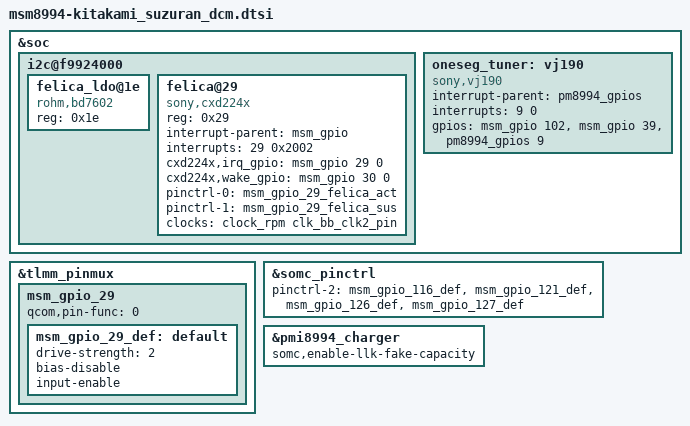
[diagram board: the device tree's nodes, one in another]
/* arch/arm/boot/dts/qcom/msm8994-kitakami_suzuran_dcm.dtsi
 *
 * This program is free software; you can redistribute it and/or modify
 * it under the terms of the GNU General Public License version 2 and
 * only version 2 as published by the Free Software Foundation.
 *
 * This program is distributed in the hope that it will be useful,
 * but WITHOUT ANY WARRANTY; without even the implied warranty of
 * MERCHANTABILITY or FITNESS FOR A PARTICULAR PURPOSE.  See the
 * GNU General Public License for more details.
 */
/*
 * Copyright (C) 2015 Sony Mobile Communications Inc.
 *
 * This program is free software; you can redistribute it and/or modify
 * it under the terms of the GNU General Public License version 2, as
 * published by the Free Software Foundation.
 */

&soc {
	i2c@f9924000 {
		felica_ldo@1e {
			compatible = "rohm,bd7602";
			reg = <0x1e>;
		};
		felica@29 {
			compatible = "sony,cxd224x";
			reg = <0x29>;
			interrupt-parent = <&msm_gpio>;
			interrupts = <29 0x2002>;
			cxd224x,irq_gpio = <&msm_gpio 29 0>;
			cxd224x,wake_gpio = <&msm_gpio 30 0>;

			pinctrl-names = "felica_active","felica_suspend";
			pinctrl-0 = <&msm_gpio_29_felica_act>;
			pinctrl-1 = <&msm_gpio_29_felica_sus>;

			clocks = <&clock_rpm clk_bb_clk2_pin>;
			clock-names = "felica_clk";
		};
	};

	oneseg_tuner: vj190 {
		compatible = "sony,vj190";
		interrupt-parent = <&pm8994_gpios>;
		interrupts = <9 0>;
		gpios = <&msm_gpio 102 0>, /* TUNER_POWER */
			<&msm_gpio 39 0>, /* TUNER_RESET */
			<&pm8994_gpios 9 0>; /* TUNER_INT */
	};
};

&tlmm_pinmux {
	/* GPIO_29: FELICA_INT_N */
	msm_gpio_29 {
		qcom,pin-func = <0>;
		msm_gpio_29_def: default {
			drive-strength = <2>;
			bias-disable;
			input-enable;
			/delete-property/ bias-pull-down;
		};
	};
};

&somc_pinctrl {
	pinctrl-2 = <&msm_gpio_116_def &msm_gpio_121_def &msm_gpio_126_def &msm_gpio_127_def>;
};

&pmi8994_charger {
	somc,enable-llk-fake-capacity;
};
